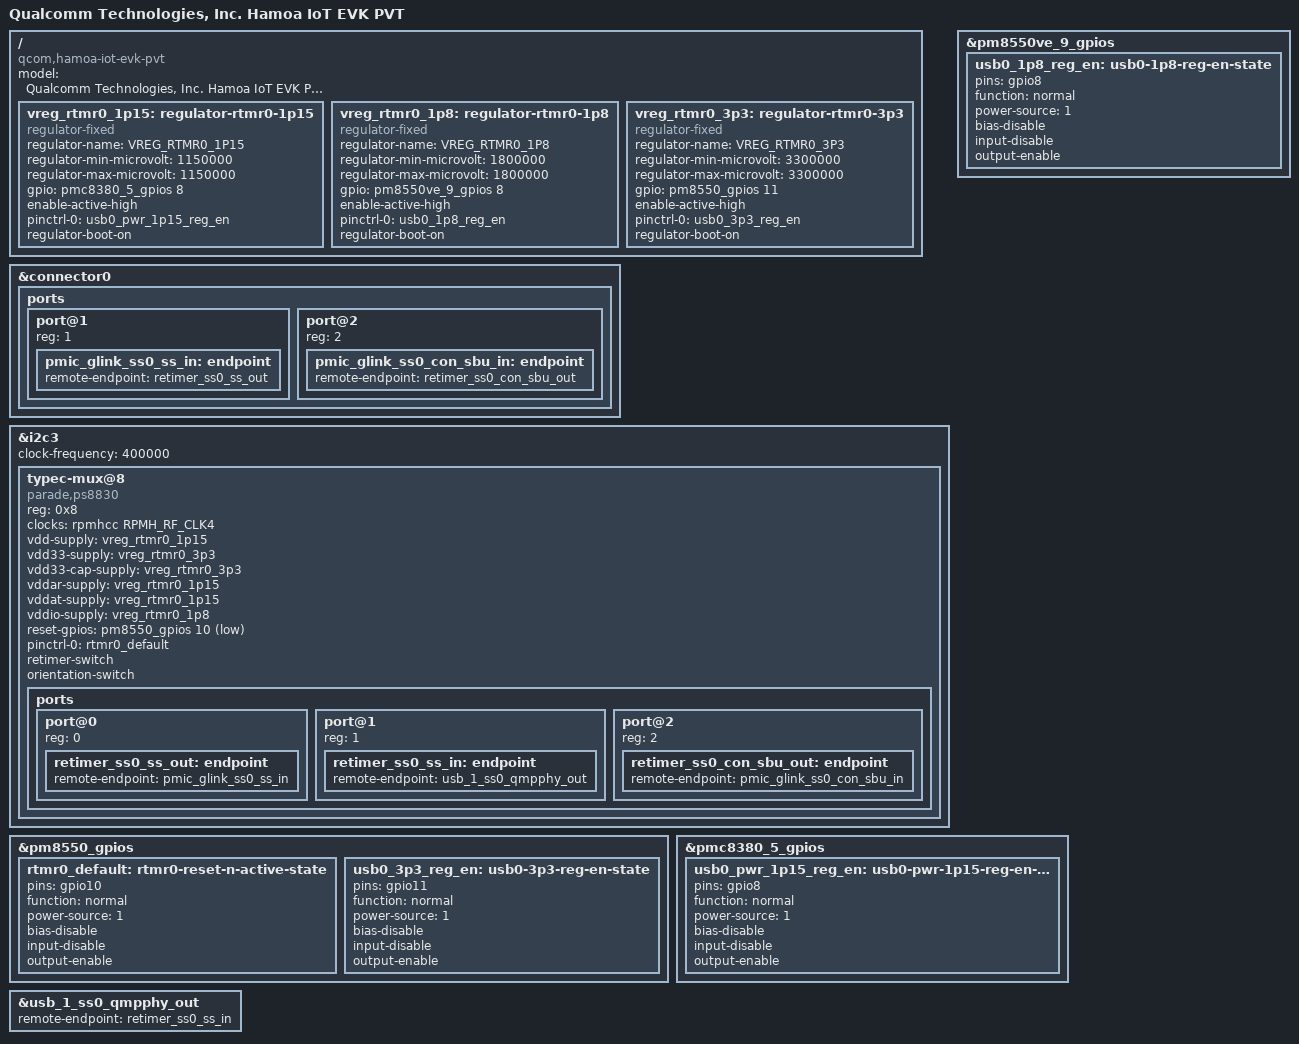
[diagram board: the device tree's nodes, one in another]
// SPDX-License-Identifier: BSD-3-Clause
/*
 * Copyright (c) Qualcomm Technologies, Inc. and/or its subsidiaries.
 */

/dts-v1/;

#include "hamoa-iot-evk.dtsi"

/ {
	model = "Qualcomm Technologies, Inc. Hamoa IoT EVK PVT";
	compatible = "qcom,hamoa-iot-evk-pvt", "qcom,hamoa-iot-evk",
		     "qcom,hamoa-iot-som", "qcom,x1e80100";

	vreg_rtmr0_1p15: regulator-rtmr0-1p15 {
		compatible = "regulator-fixed";

		regulator-name = "VREG_RTMR0_1P15";
		regulator-min-microvolt = <1150000>;
		regulator-max-microvolt = <1150000>;

		gpio = <&pmc8380_5_gpios 8 GPIO_ACTIVE_HIGH>;
		enable-active-high;

		pinctrl-0 = <&usb0_pwr_1p15_reg_en>;
		pinctrl-names = "default";

		regulator-boot-on;
	};

	vreg_rtmr0_1p8: regulator-rtmr0-1p8 {
		compatible = "regulator-fixed";

		regulator-name = "VREG_RTMR0_1P8";
		regulator-min-microvolt = <1800000>;
		regulator-max-microvolt = <1800000>;

		gpio = <&pm8550ve_9_gpios 8 GPIO_ACTIVE_HIGH>;
		enable-active-high;

		pinctrl-0 = <&usb0_1p8_reg_en>;
		pinctrl-names = "default";

		regulator-boot-on;
	};

	vreg_rtmr0_3p3: regulator-rtmr0-3p3 {
		compatible = "regulator-fixed";

		regulator-name = "VREG_RTMR0_3P3";
		regulator-min-microvolt = <3300000>;
		regulator-max-microvolt = <3300000>;

		gpio = <&pm8550_gpios 11 GPIO_ACTIVE_HIGH>;
		enable-active-high;

		pinctrl-0 = <&usb0_3p3_reg_en>;
		pinctrl-names = "default";

		regulator-boot-on;
	};
};

&connector0 {
	ports {
		port@1 {
			reg = <1>;

			pmic_glink_ss0_ss_in: endpoint {
				remote-endpoint = <&retimer_ss0_ss_out>;
			};
		};

		port@2 {
			reg = <2>;

			pmic_glink_ss0_con_sbu_in: endpoint {
				remote-endpoint = <&retimer_ss0_con_sbu_out>;
			};
		};
	};
};

&i2c3 {
	clock-frequency = <400000>;
	status = "okay";

	typec-mux@8 {
		compatible = "parade,ps8830";
		reg = <0x8>;

		clocks = <&rpmhcc RPMH_RF_CLK4>;

		vdd-supply = <&vreg_rtmr0_1p15>;
		vdd33-supply = <&vreg_rtmr0_3p3>;
		vdd33-cap-supply = <&vreg_rtmr0_3p3>;
		vddar-supply = <&vreg_rtmr0_1p15>;
		vddat-supply = <&vreg_rtmr0_1p15>;
		vddio-supply = <&vreg_rtmr0_1p8>;

		reset-gpios = <&pm8550_gpios 10 GPIO_ACTIVE_LOW>;

		pinctrl-0 = <&rtmr0_default>;
		pinctrl-names = "default";

		retimer-switch;
		orientation-switch;

		ports {
			#address-cells = <1>;
			#size-cells = <0>;

			port@0 {
				reg = <0>;

				retimer_ss0_ss_out: endpoint {
					remote-endpoint = <&pmic_glink_ss0_ss_in>;
				};
			};

			port@1 {
				reg = <1>;

				retimer_ss0_ss_in: endpoint {
					remote-endpoint = <&usb_1_ss0_qmpphy_out>;
				};
			};

			port@2 {
				reg = <2>;

				retimer_ss0_con_sbu_out: endpoint {
					remote-endpoint = <&pmic_glink_ss0_con_sbu_in>;
				};
			};

		};
	};
};

&pm8550_gpios {
	rtmr0_default: rtmr0-reset-n-active-state {
		pins = "gpio10";
		function = "normal";
		power-source = <1>; /* 1.8V */
		bias-disable;
		input-disable;
		output-enable;
	};

	usb0_3p3_reg_en: usb0-3p3-reg-en-state {
		pins = "gpio11";
		function = "normal";
		power-source = <1>; /* 1.8V */
		bias-disable;
		input-disable;
		output-enable;
	};
};

&pm8550ve_9_gpios {
	usb0_1p8_reg_en: usb0-1p8-reg-en-state {
		pins = "gpio8";
		function = "normal";
		power-source = <1>; /* 1.8V */
		bias-disable;
		input-disable;
		output-enable;
	};
};

&pmc8380_5_gpios {
	usb0_pwr_1p15_reg_en: usb0-pwr-1p15-reg-en-state {
		pins = "gpio8";
		function = "normal";
		power-source = <1>; /* 1.8V */
		bias-disable;
		input-disable;
		output-enable;
	};
};

&usb_1_ss0_qmpphy_out {
	remote-endpoint = <&retimer_ss0_ss_in>;
};
